AUTOSAR XML (schema 4-0-3)
package /ComponentTypes
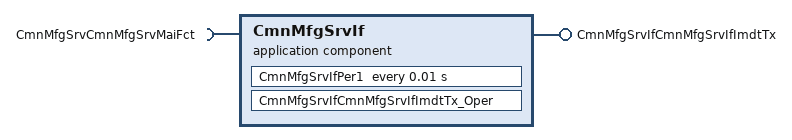
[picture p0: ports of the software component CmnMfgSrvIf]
  application sw component type CmnMfgSrvIf
    provide port CmnMfgSrvIfCmnMfgSrvIfImdtTx: server-com-spec{operation=Oper, queue-length=1}, provided-interface=CmnMfgSrvIfCmnMfgSrvIfImdtTx
    require port CmnMfgSrvCmnMfgSrvMaiFct: required-interface=CmnMfgSrvCmnMfgSrvMaiFct
    behavior CmnMfgSrvIf_InternalBehavior
      ar-typed-per-instance-memorys:
        data DataBuf: sw-calibration-access=READ-ONLY, type=Ary1D_u8_CmnMfgSrfIf
      operation invoked event OIT_CmnMfgSrvIfCmnMfgSrvIfImdtTx_Oper_CmnMfgSrvIfCmnMfgSrvIfImdtTx_Oper: start-on-event=CmnMfgSrvIfCmnMfgSrvIfImdtTx_Oper, operation=CmnMfgSrvIfCmnMfgSrvIfImdtTx.Oper
      timing event TMT_CmnMfgSrv2Per1: start-on-event=CmnMfgSrvIfPer1, period=0.01
      runnable CmnMfgSrvIfCmnMfgSrvIfImdtTx_Oper
      runnable CmnMfgSrvIfPer1
        sync call SC_CmnMfgSrvCmnMfgSrvMaiFct_Oper: operation=CmnMfgSrvCmnMfgSrvMaiFct.Oper, timeout=0
  swc implementation CmnMfgSrvIf_Implementation: behavior=CmnMfgSrvIf_InternalBehavior
    code-descriptors:
      code Default: artifact-descriptors=autosar-engineering-object={short-label=Default, category=SWSRC}
